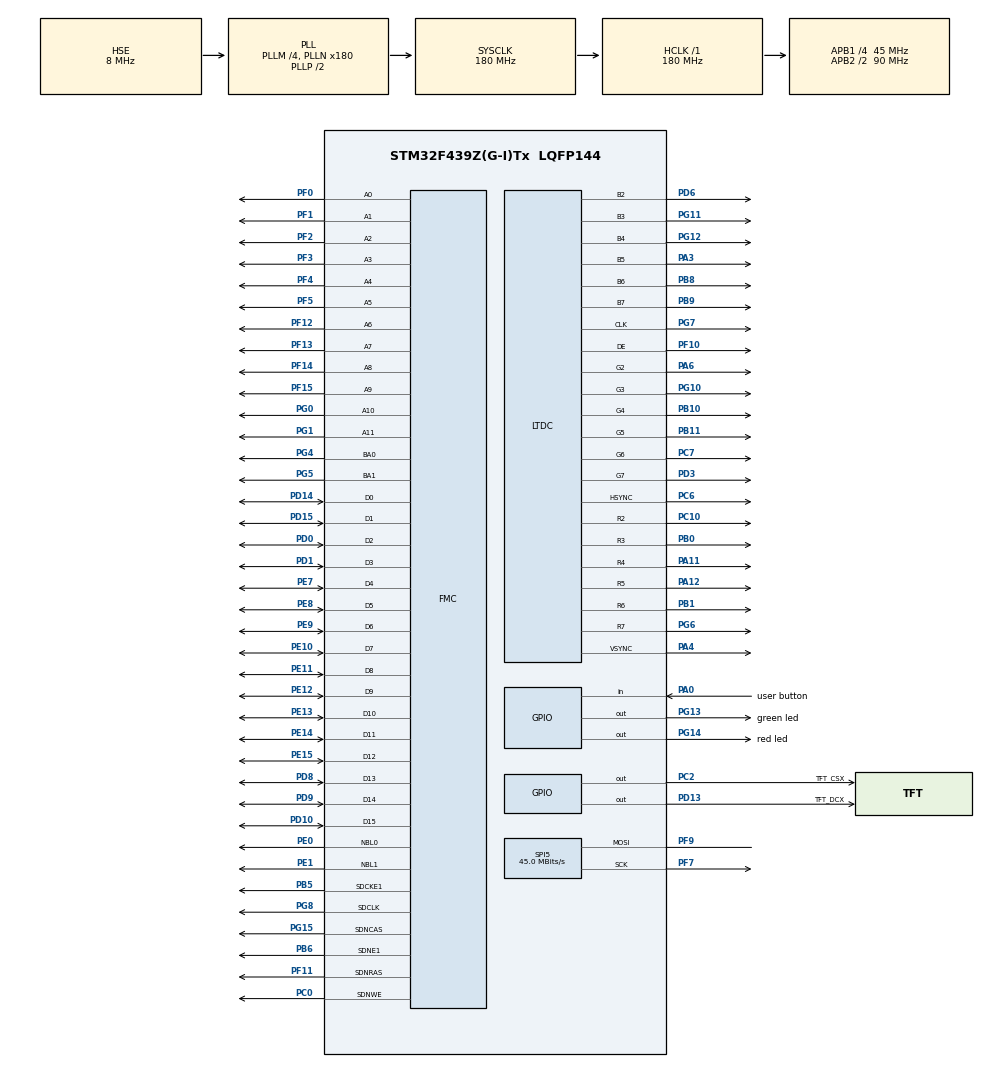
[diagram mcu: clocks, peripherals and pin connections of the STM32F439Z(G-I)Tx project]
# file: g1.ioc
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DMA2D.ColorMode=DMA2D_OUTPUT_ARGB8888
DMA2D.InputAlphaForeground=255
DMA2D.InputColorModeForeground=DMA2D_INPUT_RGB888
DMA2D.Mode=DMA2D_M2M_PFC
Dma.MEMTOMEM.0.Direction=DMA_MEMORY_TO_MEMORY
Dma.MEMTOMEM.0.FIFOMode=DMA_FIFOMODE_ENABLE
Dma.MEMTOMEM.0.FIFOThreshold=DMA_FIFO_THRESHOLD_FULL
Dma.MEMTOMEM.0.Instance=DMA2_Stream0
Dma.MEMTOMEM.0.MemBurst=DMA_MBURST_INC4
Dma.MEMTOMEM.0.MemDataAlignment=DMA_MDATAALIGN_WORD
Dma.MEMTOMEM.0.MemInc=DMA_MINC_ENABLE
Dma.MEMTOMEM.0.Mode=DMA_NORMAL
Dma.MEMTOMEM.0.PeriphBurst=DMA_PBURST_INC4
Dma.MEMTOMEM.0.PeriphDataAlignment=DMA_PDATAALIGN_WORD
Dma.MEMTOMEM.0.PeriphInc=DMA_PINC_DISABLE
Dma.MEMTOMEM.0.Priority=DMA_PRIORITY_LOW
Dma.Request0=MEMTOMEM
FMC.CASLatency1=FMC_SDRAM_CAS_LATENCY_3
FMC.ExitSelfRefreshDelay1=7
FMC.LoadToActiveDelay1=2
FMC.RCDDelay1=2
FMC.RPDelay1=2
FMC.RPDelay2=2
FMC.ReadBurst1=FMC_SDRAM_RBURST_ENABLE
FMC.ReadBurst2=FMC_SDRAM_RBURST_ENABLE
FMC.ReadPipeDelay1=FMC_SDRAM_RPIPE_DELAY_1
FMC.ReadPipeDelay2=FMC_SDRAM_RPIPE_DELAY_1
FMC.RowBitsNumber1=FMC_SDRAM_ROW_BITS_NUM_12
FMC.RowCycleDelay1=7
FMC.RowCycleDelay2=7
FMC.SDClockPeriod1=FMC_SDRAM_CLOCK_PERIOD_2
FMC.SDClockPeriod2=FMC_SDRAM_CLOCK_PERIOD_2
FMC.SelfRefreshTime1=4
FMC.WriteRecoveryTime1=3
LTDC.ActiveH=320
LTDC.ActiveW=240
LTDC.FBStartAdress_L0=0xd000000
LTDC.HBP=20
LTDC.HFP=10
LTDC.HSync=10
LTDC.ImageHeight_L0=320
LTDC.ImageWidth_L0=240
LTDC.Layers=0
LTDC.VFP=4
LTDC.VSync=2
LTDC.WindowX1_L0=240
LTDC.WindowY1_L0=320
Mcu.Family=STM32F4
Mcu.Name=STM32F439Z(G-I)Tx
Mcu.Package=LQFP144
NVIC.DMA2D_IRQn=true\:0\:0\:false\:false\:true
NVIC.DMA2_Stream0_IRQn=true\:0\:0\:false\:false\:true
NVIC.LTDC_IRQn=true\:0\:0\:false\:false\:true
NVIC.PriorityGroup=NVIC_PRIORITYGROUP_4
PA0/WKUP.GPIO_Label=user button
PA0/WKUP.Signal=GPIO_Input
PA11.Mode=RGB666
PA11.Signal=LTDC_R4
PA12.Mode=RGB666
PA12.Signal=LTDC_R5
PA13.Mode=Serial_Wire
PA13.Signal=SYS_JTMS-SWDIO
PA14.Mode=Serial_Wire
PA14.Signal=SYS_JTCK-SWCLK
PA3.Mode=RGB666
PA3.Signal=LTDC_B5
PA4.Mode=RGB666
PA4.Signal=LTDC_VSYNC
PA6.Mode=RGB666
PA6.Signal=LTDC_G2
PB0.Mode=RGB666
PB0.Signal=LTDC_R3
PB1.Mode=RGB666
PB1.Signal=LTDC_R6
PB10.Mode=RGB666
PB10.Signal=LTDC_G4
PB11.Mode=RGB666
PB11.Signal=LTDC_G5
PB5.Mode=SdramChipSelect2_1
PB5.Signal=FMC_SDCKE1
PB6.Mode=SdramChipSelect2_1
PB6.Signal=FMC_SDNE1
PB8.Mode=RGB666
PB8.Signal=LTDC_B6
PB9.Mode=RGB666
PB9.Signal=LTDC_B7
PC0.Signal=FMC_SDNWE
PC10.Mode=RGB666
PC10.Signal=LTDC_R2
PC14/OSC32_IN.Mode=LSE-External-Oscillator
PC14/OSC32_IN.Signal=RCC_OSC32_IN
PC15/OSC32_OUT.Mode=LSE-External-Oscillator
PC15/OSC32_OUT.Signal=RCC_OSC32_OUT
PC2.GPIO_Label=TFT_CSX
PC2.Signal=GPIO_Output
PC6.Mode=RGB666
PC6.Signal=LTDC_HSYNC
PC7.Mode=RGB666
PC7.Signal=LTDC_G6
PD0.Signal=FMC_D2_DA2
PD1.Signal=FMC_D3_DA3
PD10.Signal=FMC_D15_DA15
PD13.GPIO_Label=TFT_DCX
PD13.Signal=GPIO_Output
PD14.Signal=FMC_D0_DA0
PD15.Signal=FMC_D1_DA1
PD3.Mode=RGB666
PD3.Signal=LTDC_G7
PD6.Mode=RGB666
PD6.Signal=LTDC_B2
PD8.Signal=FMC_D13_DA13
PD9.Signal=FMC_D14_DA14
PE0.Signal=FMC_NBL0
PE1.Signal=FMC_NBL1
PE10.Signal=FMC_D7_DA7
PE11.Signal=FMC_D8_DA8
PE12.Signal=FMC_D9_DA9
PE13.Signal=FMC_D10_DA10
PE14.Signal=FMC_D11_DA11
PE15.Signal=FMC_D12_DA12
PE7.Signal=FMC_D4_DA4
PE8.Signal=FMC_D5_DA5
PE9.Signal=FMC_D6_DA6
PF0.Signal=FMC_A0
PF1.Signal=FMC_A1
PF10.Mode=RGB666
PF10.Signal=LTDC_DE
PF11.Signal=FMC_SDNRAS
PF12.Signal=FMC_A6
PF13.Signal=FMC_A7
PF14.Signal=FMC_A8
PF15.Signal=FMC_A9
PF2.Signal=FMC_A2
PF3.Signal=FMC_A3
PF4.Signal=FMC_A4
PF5.Signal=FMC_A5
PF7.Mode=Simplex_Bidirectional_Master
PF7.Signal=SPI5_SCK
PF9.Mode=Simplex_Bidirectional_Master
PF9.Signal=SPI5_MOSI
PG0.Signal=FMC_A10
PG1.Signal=FMC_A11
PG10.Mode=RGB666
PG10.Signal=LTDC_G3
PG11.Mode=RGB666
PG11.Signal=LTDC_B3
PG12.Mode=RGB666
PG12.Signal=LTDC_B4
PG13.GPIO_Label=green led
PG13.Signal=GPIO_Output
PG14.GPIO_Label=red led
PG14.Signal=GPIO_Output
PG15.Signal=FMC_SDNCAS
PG4.Signal=FMC_A14_BA0
PG5.Signal=FMC_A15_BA1
PG6.Mode=RGB666
PG6.Signal=LTDC_R7
PG7.Mode=RGB666
PG7.Signal=LTDC_CLK
PG8.Signal=FMC_SDCLK
PH0/OSC_IN.Mode=HSE-External-Oscillator
PH0/OSC_IN.Signal=RCC_OSC_IN
PH1/OSC_OUT.Mode=HSE-External-Oscillator
PH1/OSC_OUT.Signal=RCC_OSC_OUT
ProjectManager.HeapSize=0x200
ProjectManager.StackSize=0x400
ProjectManager.TargetToolchain=MDK-ARM V5
RCC.48MHZClocksFreq_Value=90000000
RCC.AHBFreq_Value=180000000
RCC.APB1CLKDivider=RCC_HCLK_DIV4
RCC.APB1Freq_Value=45000000
RCC.APB1TimFreq_Value=90000000
RCC.APB2CLKDivider=RCC_HCLK_DIV2
RCC.APB2Freq_Value=90000000
RCC.APB2TimFreq_Value=180000000
RCC.CortexFreq_Value=180000000
RCC.EnbaleCSS=true
RCC.HCLKFreq_Value=180000000
RCC.HSE_VALUE=8000000
RCC.HSI_VALUE=16000000
RCC.PLLM=4
RCC.PLLN=180
RCC.PLLSAIDivR=RCC_PLLSAIDIVR_16
RCC.PLLSAIN=175
RCC.PLLSAIR=4
RCC.PLLSourceVirtual=RCC_PLLSOURCE_HSE
RCC.SYSCLKFreq_VALUE=180000000
RCC.SYSCLKSource=RCC_SYSCLKSOURCE_PLLCLK
RCC.VCOOutputFreq_Value=360000000
SH.FMC_A0.0=FMC_A0,12b-sda1
SH.FMC_A1.0=FMC_A1,12b-sda1
SH.FMC_A10.0=FMC_A10,12b-sda1
SH.FMC_A11.0=FMC_A11,12b-sda1
SH.FMC_A14_BA0.0=FMC_BA0,FourSdramBanks1
SH.FMC_A15_BA1.0=FMC_BA1,FourSdramBanks1
SH.FMC_A2.0=FMC_A2,12b-sda1
SH.FMC_A3.0=FMC_A3,12b-sda1
SH.FMC_A4.0=FMC_A4,12b-sda1
SH.FMC_A5.0=FMC_A5,12b-sda1
SH.FMC_A6.0=FMC_A6,12b-sda1
SH.FMC_A7.0=FMC_A7,12b-sda1
SH.FMC_A8.0=FMC_A8,12b-sda1
SH.FMC_A9.0=FMC_A9,12b-sda1
SH.FMC_D0_DA0.0=FMC_D0,sd-16b-d1
SH.FMC_D10_DA10.0=FMC_D10,sd-16b-d1
SH.FMC_D11_DA11.0=FMC_D11,sd-16b-d1
SH.FMC_D12_DA12.0=FMC_D12,sd-16b-d1
SH.FMC_D13_DA13.0=FMC_D13,sd-16b-d1
SH.FMC_D14_DA14.0=FMC_D14,sd-16b-d1
SH.FMC_D15_DA15.0=FMC_D15,sd-16b-d1
SH.FMC_D1_DA1.0=FMC_D1,sd-16b-d1
SH.FMC_D2_DA2.0=FMC_D2,sd-16b-d1
SH.FMC_D3_DA3.0=FMC_D3,sd-16b-d1
SH.FMC_D4_DA4.0=FMC_D4,sd-16b-d1
SH.FMC_D5_DA5.0=FMC_D5,sd-16b-d1
SH.FMC_D6_DA6.0=FMC_D6,sd-16b-d1
SH.FMC_D7_DA7.0=FMC_D7,sd-16b-d1
SH.FMC_D8_DA8.0=FMC_D8,sd-16b-d1
SH.FMC_D9_DA9.0=FMC_D9,sd-16b-d1
SH.FMC_NBL0.0=FMC_NBL0,Sd2ByteEnable1
SH.FMC_NBL1.0=FMC_NBL1,Sd2ByteEnable1
SH.FMC_SDCLK.0=FMC_SDCLK,12b-sda1
SH.FMC_SDNCAS.0=FMC_SDNCAS,12b-sda1
SH.FMC_SDNRAS.0=FMC_SDNRAS,12b-sda1
SH.FMC_SDNWE.0=FMC_SDNWE,12b-sda1
SPI5.CalculateBaudRate=45.0 MBits/s
SPI5.Direction=SPI_DIRECTION_1LINE
SPI5.Mode=SPI_MODE_MASTER
VP_DMA2D_VS_DMA2D.Mode=DMA2D_Activate
board=g1

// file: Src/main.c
/**
  ******************************************************************************
  * File Name          : main.c
  * Description        : Main program body
  ******************************************************************************
  *
  * COPYRIGHT(c) 2016 STMicroelectronics
  *
  * Redistribution and use in source and binary forms, with or without modification,
  * are permitted provided that the following conditions are met:
  *   1. Redistributions of source code must retain the above copyright notice,
  *      this list of conditions and the following disclaimer.
  *   2. Redistributions in binary form must reproduce the above copyright notice,
  *      this list of conditions and the following disclaimer in the documentation
  *      and/or other materials provided with the distribution.
  *   3. Neither the name of STMicroelectronics nor the names of its contributors
  *      may be used to endorse or promote products derived from this software
  *      without specific prior written permission.
  *
  * THIS SOFTWARE IS PROVIDED BY THE COPYRIGHT HOLDERS AND CONTRIBUTORS "AS IS"
  * AND ANY EXPRESS OR IMPLIED WARRANTIES, INCLUDING, BUT NOT LIMITED TO, THE
  * IMPLIED WARRANTIES OF MERCHANTABILITY AND FITNESS FOR A PARTICULAR PURPOSE ARE
  * DISCLAIMED. IN NO EVENT SHALL THE COPYRIGHT HOLDER OR CONTRIBUTORS BE LIABLE
  * FOR ANY DIRECT, INDIRECT, INCIDENTAL, SPECIAL, EXEMPLARY, OR CONSEQUENTIAL
  * DAMAGES (INCLUDING, BUT NOT LIMITED TO, PROCUREMENT OF SUBSTITUTE GOODS OR
  * SERVICES; LOSS OF USE, DATA, OR PROFITS; OR BUSINESS INTERRUPTION) HOWEVER
  * CAUSED AND ON ANY THEORY OF LIABILITY, WHETHER IN CONTRACT, STRICT LIABILITY,
  * OR TORT (INCLUDING NEGLIGENCE OR OTHERWISE) ARISING IN ANY WAY OUT OF THE USE
  * OF THIS SOFTWARE, EVEN IF ADVISED OF THE POSSIBILITY OF SUCH DAMAGE.
  *
  ******************************************************************************
  */
#include <stdlib.h>
#include "stm32f4xx_hal.h"
//#include "ili9341.h"

/* USER CODE BEGIN Includes */
#include <stdlib.h>
extern unsigned char const bibe[240 * 320 * 3 + 1];

extern unsigned char const f1[240 * 320 * 3 + 1];
extern unsigned char const f2[240 * 320 * 3 + 1];
extern unsigned char const f3[240 * 320 * 3 + 1];
extern unsigned char const f4[240 * 320 * 3 + 1];
extern unsigned char const f5[240 * 320 * 3 + 1];
extern unsigned char const f6[240 * 320 * 3 + 1];
/* USER CODE END Includes */

DMA2D_HandleTypeDef hdma2d;

LTDC_HandleTypeDef hltdc;

SPI_HandleTypeDef hspi5;

DMA_HandleTypeDef hdma_memtomem_dma2_stream0;
SDRAM_HandleTypeDef hsdram1;

/* USER CODE BEGIN PV */
/* Private variables ---------------------------------------------------------*/

/* USER CODE END PV */

void SystemClock_Config(void);
void Error_Handler(void);
static void MX_GPIO_Init(void);
static void MX_DMA_Init(void);
static void MX_FMC_Init(void);
static void MX_DMA2D_Init(void);
static void MX_LTDC_Init(void);
static void MX_SPI5_Init(void);

/* USER CODE BEGIN PFP */
/* Private function prototypes -----------------------------------------------*/

/* USER CODE END PFP */

/* USER CODE BEGIN 0 */
static volatile uint32_t pattern = 0xff00ff00;
static volatile uint32_t read_pattern = 0;
static uint32_t sdram_start_address = 0xd0000000;
static uint32_t *p;
volatile uint32_t i;
volatile uint32_t start,stop,delta;

static FMC_SDRAM_CommandTypeDef Command;
void BSP_SDRAM_Initialization_sequence(uint32_t RefreshCount)
{
  __IO uint32_t tmpmrd =0;

  /* Step 1:  Configure a clock configuration enable command */
  Command.CommandMode             = FMC_SDRAM_CMD_CLK_ENABLE;
  Command.CommandTarget           = FMC_SDRAM_CMD_TARGET_BANK2;
  Command.AutoRefreshNumber       = 1;
  Command.ModeRegisterDefinition  = 0;

  /* Send the command */
  HAL_SDRAM_SendCommand(&hsdram1, &Command, 0xFFFF);

  /* Step 2: Insert 100 us minimum delay */
  /* Inserted delay is equal to 1 ms due to systick time base unit (ms) */
  HAL_Delay(1);

  /* Step 3: Configure a PALL (precharge all) command */
  Command.CommandMode             = FMC_SDRAM_CMD_PALL;
  Command.CommandTarget           = FMC_SDRAM_CMD_TARGET_BANK2;
  Command.AutoRefreshNumber       = 1;
  Command.ModeRegisterDefinition  = 0;

  /* Send the command */
  HAL_SDRAM_SendCommand(&hsdram1, &Command, 0xFFFF);

  /* Step 4: Configure an Auto Refresh command */
  Command.CommandMode             = FMC_SDRAM_CMD_AUTOREFRESH_MODE;
  Command.CommandTarget           = FMC_SDRAM_CMD_TARGET_BANK2;
  Command.AutoRefreshNumber       = 4;
  Command.ModeRegisterDefinition  = 0;

  /* Send the command */
  HAL_SDRAM_SendCommand(&hsdram1, &Command, 0xFFFF);

  /* Step 5: Program the external memory mode register */
  tmpmrd = (uint32_t)0x0002          |
                     0   |
                     0x0030           |
                     0 |
                     0x0200;

  Command.CommandMode             = FMC_SDRAM_CMD_LOAD_MODE;
  Command.CommandTarget           = FMC_SDRAM_CMD_TARGET_BANK2;
  Command.AutoRefreshNumber       = 1;
  Command.ModeRegisterDefinition  = tmpmrd;

  /* Send the command */
  HAL_SDRAM_SendCommand(&hsdram1, &Command, 0xFFFF);

  /* Step 6: Set the refresh rate counter */
  /* Set the device refresh rate */
  HAL_SDRAM_ProgramRefreshRate(&hsdram1, RefreshCount);
}

volatile uint32_t done = 0;
void myDMA_Callback(DMA_HandleTypeDef *_hdma)
{
	done = 1;
}

uint32_t *dpo = (uint32_t*)0xd0000000;
uint16_t pi = 240;
void drawset2(float sx,float ex, float sy, float ey);
/* USER CODE END 0 */

int main(void)
{

  /* MCU Configuration----------------------------------------------------------*/

  /* Reset of all peripherals, Initializes the Flash interface and the Systick. */
  HAL_Init();

  /* Configure the system clock */
  SystemClock_Config();

  /* Initialize all configured peripherals */
  MX_GPIO_Init();
  MX_DMA_Init();
  MX_FMC_Init();
  MX_DMA2D_Init();
  MX_LTDC_Init();
  MX_SPI5_Init();

  /* Infinite loop */
  /* USER CODE BEGIN WHILE */
	HAL_GPIO_TogglePin(green_led_GPIO_Port,green_led_Pin);
  while (1)
  {
  /* USER CODE END WHILE */

  /* USER CODE BEGIN 3 */
		HAL_GPIO_TogglePin(red_led_GPIO_Port,red_led_Pin);
		HAL_GPIO_TogglePin(green_led_GPIO_Port,green_led_Pin);
		HAL_Delay(1000);

		p = (uint32_t*)sdram_start_address;
		//r(i=0;i<8*1024*1024;i+=4){
			//HAL_SDRAM_Write_32b(&hsdram1,(uint32_t*)(sdram_start_address+i),&pattern,1);
			//(__IO uint32_t *)(p++) = pattern;
//}

		//L_DMA_XFER_CPLT_CB_ID
		pattern = rand();

		HAL_DMA_RegisterCallback(&hdma_memtomem_dma2_stream0,HAL_DMA_XFER_CPLT_CB_ID,myDMA_Callback);
		for(i=0;i<2;i++){
			HAL_DMA_Start_IT(&hdma_memtomem_dma2_stream0,
			(uint32_t)&pattern,
			(uint32_t)p,38400);
			p+=38400;
			while(!done);
			done = 0;
		}
		HAL_Delay(1000);
		start = HAL_GetTick();
	//todo add mandelbrot here
		{
			 float sx,ex,sy,ey;
			 float	zof = 0.00001;
		   float zfi = 0.00001;
			sx = -1.4481471; ex = -1.4472926; sy = -0.0012840417; ey = -0.00030747990;

			while(zof<0.00163999794){

				drawset2(sx, ex, sy, ey);

				zof+=zfi;
				sx -= zof;
				ex += zof;
				sy -= zof;
				ey += zof;

				HAL_Delay(16);
			}

		}
		//HAL_Delay(1000);
		//drawset2(-1.4494717,-1.4477627,-0.0017153568,0.00023776683);

		stop = HAL_GetTick();
		delta = stop- start;
		#if 0
		p = (uint32_t*)sdram_start_address;
		for(i=0;i<128*65532;i+=4){
			//HAL_SDRAM_Read_32b(&hsdram1,(uint32_t*)(sdram_start_address+i),&read_pattern,1);
			read_pattern = *(__IO uint32_t *)(p++);
			if(read_pattern!=0xaa55aa55)
			{
				while(1){
					HAL_GPIO_TogglePin(red_led_GPIO_Port,red_led_Pin);
					HAL_GPIO_TogglePin(green_led_GPIO_Port,green_led_Pin);
					HAL_Delay(50);
				}
			}
		}
		stop = HAL_GetTick();
		delta = stop- start;
		#endif

  }
  /* USER CODE END 3 */

}

/** System Clock Configuration
*/
void SystemClock_Config(void)
{

  RCC_OscInitTypeDef RCC_OscInitStruct;
  RCC_ClkInitTypeDef RCC_ClkInitStruct;
  RCC_PeriphCLKInitTypeDef PeriphClkInitStruct;

  __HAL_RCC_PWR_CLK_ENABLE();

  __HAL_PWR_VOLTAGESCALING_CONFIG(PWR_REGULATOR_VOLTAGE_SCALE1);

  RCC_OscInitStruct.OscillatorType = RCC_OSCILLATORTYPE_HSE;
  RCC_OscInitStruct.HSEState = RCC_HSE_ON;
  RCC_OscInitStruct.PLL.PLLState = RCC_PLL_ON;
  RCC_OscInitStruct.PLL.PLLSource = RCC_PLLSOURCE_HSE;
  RCC_OscInitStruct.PLL.PLLM = 4;
  RCC_OscInitStruct.PLL.PLLN = 180;
  RCC_OscInitStruct.PLL.PLLP = RCC_PLLP_DIV2;
  RCC_OscInitStruct.PLL.PLLQ = 4;
  if (HAL_RCC_OscConfig(&RCC_OscInitStruct) != HAL_OK)
  {
    Error_Handler();
  }

  if (HAL_PWREx_EnableOverDrive() != HAL_OK)
  {
    Error_Handler();
  }

  RCC_ClkInitStruct.ClockType = RCC_CLOCKTYPE_HCLK|RCC_CLOCKTYPE_SYSCLK
                              |RCC_CLOCKTYPE_PCLK1|RCC_CLOCKTYPE_PCLK2;
  RCC_ClkInitStruct.SYSCLKSource = RCC_SYSCLKSOURCE_PLLCLK;
  RCC_ClkInitStruct.AHBCLKDivider = RCC_SYSCLK_DIV1;
  RCC_ClkInitStruct.APB1CLKDivider = RCC_HCLK_DIV4;
  RCC_ClkInitStruct.APB2CLKDivider = RCC_HCLK_DIV2;
  if (HAL_RCC_ClockConfig(&RCC_ClkInitStruct, FLASH_LATENCY_5) != HAL_OK)
  {
    Error_Handler();
  }

  PeriphClkInitStruct.PeriphClockSelection = RCC_PERIPHCLK_LTDC;
  PeriphClkInitStruct.PLLSAI.PLLSAIN = 175;
  PeriphClkInitStruct.PLLSAI.PLLSAIR = 4;
  PeriphClkInitStruct.PLLSAIDivR = RCC_PLLSAIDIVR_16;
  if (HAL_RCCEx_PeriphCLKConfig(&PeriphClkInitStruct) != HAL_OK)
  {
    Error_Handler();
  }

  HAL_RCC_EnableCSS();

  HAL_SYSTICK_Config(HAL_RCC_GetHCLKFreq()/1000);

  HAL_SYSTICK_CLKSourceConfig(SYSTICK_CLKSOURCE_HCLK);

  /* SysTick_IRQn interrupt configuration */
  HAL_NVIC_SetPriority(SysTick_IRQn, 0, 0);
}

/* DMA2D init function */
static void MX_DMA2D_Init(void)
{

  hdma2d.Instance = DMA2D;
  hdma2d.Init.Mode = DMA2D_M2M_PFC;
  hdma2d.Init.ColorMode = DMA2D_OUTPUT_ARGB8888;
  hdma2d.Init.OutputOffset = 0;
  hdma2d.LayerCfg[1].InputOffset = 0;
  hdma2d.LayerCfg[1].InputColorMode = DMA2D_INPUT_RGB888;
  hdma2d.LayerCfg[1].AlphaMode = DMA2D_NO_MODIF_ALPHA;
  hdma2d.LayerCfg[1].InputAlpha = 255;
  if (HAL_DMA2D_Init(&hdma2d) != HAL_OK)
  {
    Error_Handler();
  }

  if (HAL_DMA2D_ConfigLayer(&hdma2d, 1) != HAL_OK)
  {
    Error_Handler();
  }

}

/* LTDC init function */
static void MX_LTDC_Init(void)
{

  LTDC_LayerCfgTypeDef pLayerCfg;
  ili9341_Init();

  hltdc.Instance = LTDC;
  hltdc.Init.HSPolarity = LTDC_HSPOLARITY_AL;
  hltdc.Init.VSPolarity = LTDC_VSPOLARITY_AL;
  hltdc.Init.DEPolarity = LTDC_DEPOLARITY_AL;
  hltdc.Init.PCPolarity = LTDC_PCPOLARITY_IPC;
  hltdc.Init.HorizontalSync = 9;
  hltdc.Init.VerticalSync = 1;
  hltdc.Init.AccumulatedHBP = 29;
  hltdc.Init.AccumulatedVBP = 3;
  hltdc.Init.AccumulatedActiveW = 269;
  hltdc.Init.AccumulatedActiveH = 323;
  hltdc.Init.TotalWidth = 279;
  hltdc.Init.TotalHeigh = 327;
  hltdc.Init.Backcolor.Blue = 0;
  hltdc.Init.Backcolor.Green = 0;
  hltdc.Init.Backcolor.Red = 0;
  if (HAL_LTDC_Init(&hltdc) != HAL_OK)
  {
    Error_Handler();
  }

  pLayerCfg.WindowX0 = 0;
  pLayerCfg.WindowX1 = 240;
  pLayerCfg.WindowY0 = 0;
  pLayerCfg.WindowY1 = 320;
  pLayerCfg.PixelFormat = LTDC_PIXEL_FORMAT_ARGB8888;
  pLayerCfg.Alpha = 255;
  pLayerCfg.Alpha0 = 0;
  pLayerCfg.BlendingFactor1 = LTDC_BLENDING_FACTOR1_CA;
  pLayerCfg.BlendingFactor2 = LTDC_BLENDING_FACTOR2_CA;
  pLayerCfg.FBStartAdress = 0xd0000000;
  pLayerCfg.ImageWidth = 240;
  pLayerCfg.ImageHeight = 320;
  pLayerCfg.Backcolor.Blue = 0;
  pLayerCfg.Backcolor.Green = 255;
  pLayerCfg.Backcolor.Red = 0;
  if (HAL_LTDC_ConfigLayer(&hltdc, &pLayerCfg, 0) != HAL_OK)
  {
    Error_Handler();
  }

}

/* SPI5 init function */
static void MX_SPI5_Init(void)
{

  hspi5.Instance = SPI5;
  hspi5.Init.Mode = SPI_MODE_MASTER;
  hspi5.Init.Direction = SPI_DIRECTION_1LINE;
  hspi5.Init.DataSize = SPI_DATASIZE_8BIT;
  hspi5.Init.CLKPolarity = SPI_POLARITY_LOW;
  hspi5.Init.CLKPhase = SPI_PHASE_1EDGE;
  hspi5.Init.NSS = SPI_NSS_SOFT;
  hspi5.Init.BaudRatePrescaler = SPI_BAUDRATEPRESCALER_2;
  hspi5.Init.FirstBit = SPI_FIRSTBIT_MSB;
  hspi5.Init.TIMode = SPI_TIMODE_DISABLE;
  hspi5.Init.CRCCalculation = SPI_CRCCALCULATION_DISABLE;
  hspi5.Init.CRCPolynomial = 10;
  if (HAL_SPI_Init(&hspi5) != HAL_OK)
  {
    Error_Handler();
  }

}

static void MX_DMA_Init(void)
{
  /* DMA controller clock enable */
  __HAL_RCC_DMA2_CLK_ENABLE();

  /* Configure DMA request hdma_memtomem_dma2_stream0 on DMA2_Stream0 */
  hdma_memtomem_dma2_stream0.Instance = DMA2_Stream0;
  hdma_memtomem_dma2_stream0.Init.Channel = DMA_CHANNEL_0;
  hdma_memtomem_dma2_stream0.Init.Direction = DMA_MEMORY_TO_MEMORY;
  hdma_memtomem_dma2_stream0.Init.PeriphInc = DMA_PINC_DISABLE;
  hdma_memtomem_dma2_stream0.Init.MemInc = DMA_MINC_ENABLE;
  hdma_memtomem_dma2_stream0.Init.PeriphDataAlignment = DMA_PDATAALIGN_WORD;
  hdma_memtomem_dma2_stream0.Init.MemDataAlignment = DMA_MDATAALIGN_WORD;
  hdma_memtomem_dma2_stream0.Init.Mode = DMA_NORMAL;
  hdma_memtomem_dma2_stream0.Init.Priority = DMA_PRIORITY_LOW;
  hdma_memtomem_dma2_stream0.Init.FIFOMode = DMA_FIFOMODE_ENABLE;
  hdma_memtomem_dma2_stream0.Init.FIFOThreshold = DMA_FIFO_THRESHOLD_FULL;
  hdma_memtomem_dma2_stream0.Init.MemBurst = DMA_MBURST_INC4;
  hdma_memtomem_dma2_stream0.Init.PeriphBurst = DMA_PBURST_INC4;
  if (HAL_DMA_Init(&hdma_memtomem_dma2_stream0) != HAL_OK)
  {
    Error_Handler();
  }

  /* DMA interrupt init */
  /* DMA2_Stream0_IRQn interrupt configuration */
  HAL_NVIC_SetPriority(DMA2_Stream0_IRQn, 0, 0);
  HAL_NVIC_EnableIRQ(DMA2_Stream0_IRQn);

}
/* FMC initialization function */
static void MX_FMC_Init(void)
{
  FMC_SDRAM_TimingTypeDef SdramTiming;

  /** Perform the SDRAM1 memory initialization sequence
  */
  hsdram1.Instance = FMC_SDRAM_DEVICE;
  /* hsdram1.Init */
  hsdram1.Init.SDBank = FMC_SDRAM_BANK2;
  hsdram1.Init.ColumnBitsNumber = FMC_SDRAM_COLUMN_BITS_NUM_8;
  hsdram1.Init.RowBitsNumber = FMC_SDRAM_ROW_BITS_NUM_12;
  hsdram1.Init.MemoryDataWidth = FMC_SDRAM_MEM_BUS_WIDTH_16;
  hsdram1.Init.InternalBankNumber = FMC_SDRAM_INTERN_BANKS_NUM_4;
  hsdram1.Init.CASLatency = FMC_SDRAM_CAS_LATENCY_3;
  hsdram1.Init.WriteProtection = FMC_SDRAM_WRITE_PROTECTION_DISABLE;
  hsdram1.Init.SDClockPeriod = FMC_SDRAM_CLOCK_PERIOD_2;
  hsdram1.Init.ReadBurst = FMC_SDRAM_RBURST_ENABLE;
  hsdram1.Init.ReadPipeDelay = FMC_SDRAM_RPIPE_DELAY_1;
  /* SdramTiming */
  SdramTiming.LoadToActiveDelay = 2;
  SdramTiming.ExitSelfRefreshDelay = 7;
  SdramTiming.SelfRefreshTime = 4;
  SdramTiming.RowCycleDelay = 7;
  SdramTiming.WriteRecoveryTime = 3;
  SdramTiming.RPDelay = 2;
  SdramTiming.RCDDelay = 2;

  if (HAL_SDRAM_Init(&hsdram1, &SdramTiming) != HAL_OK)
  {
    Error_Handler();
  }
	BSP_SDRAM_Initialization_sequence(1386);

}

/** Configure pins as
        * Analog
        * Input
        * Output
        * EVENT_OUT
        * EXTI
*/
static void MX_GPIO_Init(void)
{

  GPIO_InitTypeDef GPIO_InitStruct;

  /* GPIO Ports Clock Enable */
  __HAL_RCC_GPIOC_CLK_ENABLE();
  __HAL_RCC_GPIOF_CLK_ENABLE();
  __HAL_RCC_GPIOH_CLK_ENABLE();
  __HAL_RCC_GPIOA_CLK_ENABLE();
  __HAL_RCC_GPIOB_CLK_ENABLE();
  __HAL_RCC_GPIOG_CLK_ENABLE();
  __HAL_RCC_GPIOE_CLK_ENABLE();
  __HAL_RCC_GPIOD_CLK_ENABLE();

  /*Configure GPIO pin Output Level */
  HAL_GPIO_WritePin(TFT_CSX_GPIO_Port, TFT_CSX_Pin, GPIO_PIN_RESET);

  /*Configure GPIO pin Output Level */
  HAL_GPIO_WritePin(TFT_DCX_GPIO_Port, TFT_DCX_Pin, GPIO_PIN_RESET);

  /*Configure GPIO pin Output Level */
  HAL_GPIO_WritePin(GPIOG, green_led_Pin|red_led_Pin, GPIO_PIN_RESET);

  /*Configure GPIO pin : TFT_CSX_Pin */
  GPIO_InitStruct.Pin = TFT_CSX_Pin;
  GPIO_InitStruct.Mode = GPIO_MODE_OUTPUT_PP;
  GPIO_InitStruct.Pull = GPIO_NOPULL;
  GPIO_InitStruct.Speed = GPIO_SPEED_FREQ_LOW;
  HAL_GPIO_Init(TFT_CSX_GPIO_Port, &GPIO_InitStruct);

  /*Configure GPIO pin : user_button_Pin */
  GPIO_InitStruct.Pin = user_button_Pin;
  GPIO_InitStruct.Mode = GPIO_MODE_INPUT;
  GPIO_InitStruct.Pull = GPIO_NOPULL;
  HAL_GPIO_Init(user_button_GPIO_Port, &GPIO_InitStruct);

  /*Configure GPIO pin : TFT_DCX_Pin */
  GPIO_InitStruct.Pin = TFT_DCX_Pin;
  GPIO_InitStruct.Mode = GPIO_MODE_OUTPUT_PP;
  GPIO_InitStruct.Pull = GPIO_NOPULL;
  GPIO_InitStruct.Speed = GPIO_SPEED_FREQ_LOW;
  HAL_GPIO_Init(TFT_DCX_GPIO_Port, &GPIO_InitStruct);

  /*Configure GPIO pins : green_led_Pin red_led_Pin */
  GPIO_InitStruct.Pin = green_led_Pin|red_led_Pin;
  GPIO_InitStruct.Mode = GPIO_MODE_OUTPUT_PP;
  GPIO_InitStruct.Pull = GPIO_NOPULL;
  GPIO_InitStruct.Speed = GPIO_SPEED_FREQ_LOW;
  HAL_GPIO_Init(GPIOG, &GPIO_InitStruct);

}

void Error_Handler(void)
{
  while(1)
  {
  }
}

/************************ (C) COPYRIGHT STMicroelectronics *****END OF FILE****/
